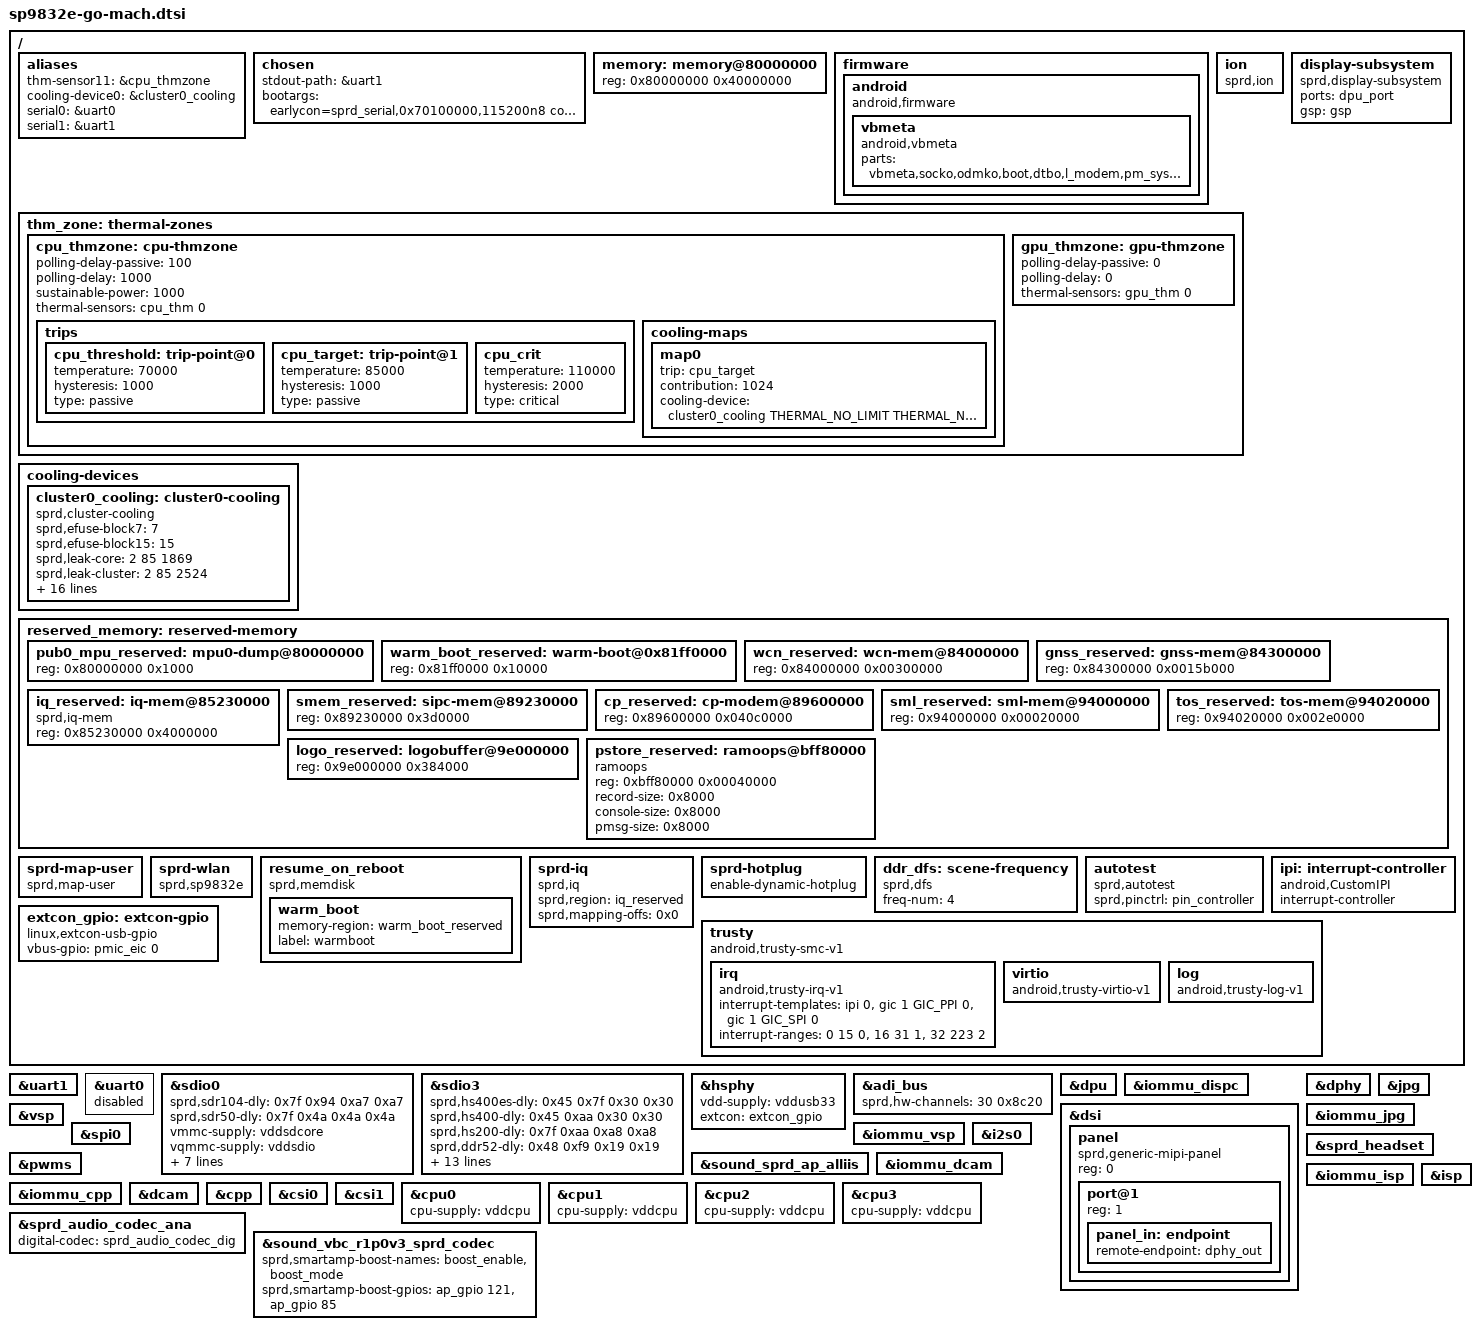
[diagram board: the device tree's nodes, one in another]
/*
 * Spreadtrum SP98x0 board common DTS file
 *
 * Copyright (C) 2019, Spreadtrum Communications Inc.
 *
 * This file is licensed under a dual GPLv2 or X11 license.
 */

#include <dt-bindings/thermal/thermal.h>
#include "sc9832e-modem.dtsi"

/ {
	aliases {
		thm-sensor11 = &cpu_thmzone;
		cooling-device0 = &cluster0_cooling;
		serial0 = &uart0;
		serial1 = &uart1;
	};

	chosen: chosen {
		stdout-path = &uart1;
		bootargs = "earlycon=sprd_serial,0x70100000,115200n8 console=ttyS1,115200n8 loglevel=1 init=/init root=/dev/ram0 rw vmalloc=360M printk.devkmsg=on androidboot.boot_devices=soc/soc:ap-ahb/20600000.sdio";
	};

	memory: memory@80000000 {
		device_type = "memory";
		reg = <0x80000000 0x40000000>;
	};

	firmware {
		android {
			compatible = "android,firmware";
			vbmeta {
				compatible = "android,vbmeta";
				parts = "vbmeta,socko,odmko,boot,dtbo,l_modem,pm_sys,l_ldsp,l_gdsp";
			};
		};
	};

	ion: ion {
		compatible = "sprd,ion";
		#address-cells = <1>;
		#size-cells = <0>;

	};

	thm_zone: thermal-zones {

		cpu_thmzone: cpu-thmzone {
			polling-delay-passive = <100>;
			polling-delay = <1000>;
			sustainable-power = <1000>;
			thermal-sensors = <&cpu_thm 0>;
			trips {
				cpu_threshold: trip-point@0 {
					temperature = <70000>;
					hysteresis = <1000>;
					type = "passive";
				};
				cpu_target: trip-point@1 {
					temperature = <85000>;
					hysteresis = <1000>;
					type = "passive";
				};
				cpu_crit: cpu_crit {
					temperature = <110000>;
					hysteresis = <2000>;
					type = "critical";
				};
			};

			cooling-maps {
				map0 {
					trip = <&cpu_target>;
					contribution = <1024>;
					cooling-device =
					<&cluster0_cooling
						THERMAL_NO_LIMIT
						THERMAL_NO_LIMIT>;
				};
			};

		};

		gpu_thmzone: gpu-thmzone {
			polling-delay-passive = <0>;
			polling-delay = <0>;
			thermal-sensors = <&gpu_thm 0>;
		};
	};

	cooling-devices {
		cluster0_cooling: cluster0-cooling {
			compatible = "sprd,cluster-cooling";
			#cooling-cells = <2>; /* min followed by max */
			sprd,efuse-block7 = <7>;
			sprd,efuse-block15 = <15>;
			/* core_leak =                             */
			/*(LIT_LEAK[4:0]+1) x 2mA x 0.85V x 18.69% */
			sprd,leak-core = <2 85 1869>;
			/* cluster_leak =                           */
			/* (LIT_LEAK[4:0]+1) x 2mA x 0.85V x 25.24% */
			sprd,leak-cluster = <2 85 2524>;
			/*core Tscale = aT^3 + bT^2 + cT +di   */
			sprd,core-temp-scale =
			/* a*10^7   b*10^7      c*10^7     d*10^7 */
			<  34       (-3000)     147000     (-1367000)>;
			/*core Vscale = eV^3 + fV^2 + gV + h */
			sprd,core-voltage-scale =
			/* e*10^2   f*10^2     g*10^2  h*10^2*/
			<  2863     (-7860)    7541    (-2408)>;
			/*cluster Tscale = aT^3 + bT^2 + cT +di   */
			sprd,cluster-temp-scale =
			/* a*10^7   b*10^7      c*10^7     d*10^7 */
			<  26       (-2000)     115000     (-1000000)>;
			/*cluster Vscale = eV^3 + fV^2 + gV + h */
			sprd,cluster-voltage-scale =
			/* e*10^2   f*10^2     g*10^2  h*10^2*/
			<  1582     (-4201)    4063    (-1307)>;
			sprd,efuse-switch = <0>;
			sprd,hotplug-period = <10>;
			sprd,min-cpufreq = <768000>;
			sprd,min-cpunum = <4>;
			sprd,core-base = <267>;
			sprd,cluster-base = <294>;
			sprd,dynamic-core =
			/*Pdynperghz    Freq     Vbase  */
			< 850          768       900>;
			sprd,dynamic-cluster =
			/*Pdynperghz    Freq     Vbase  */
			< 980           768      900>;
		};
	};

	display-subsystem {
		compatible = "sprd,display-subsystem";
		ports = <&dpu_port>;
		gsp = <&gsp>;
	};

	reserved_memory: reserved-memory {
		#address-cells = <1>;
		#size-cells = <1>;
		ranges;

		pub0_mpu_reserved: mpu0-dump@80000000 {
			reg = <0x80000000 0x1000>;
		};

		warm_boot_reserved: warm-boot@0x81ff0000 {
			reg = <0x81ff0000 0x10000>; /* 64K */
		};

		/* must be 32M aligned */
		wcn_reserved: wcn-mem@84000000 {
			reg = <0x84000000 0x00300000>;
		};

		gnss_reserved: gnss-mem@84300000 {
			reg = <0x84300000 0x0015b000>;
		};

		/* Only used for iq, will be removed in normal mode by uboot */
		iq_reserved: iq-mem@85230000 {
			compatible = "sprd,iq-mem";
			reg = <0x85230000 0x4000000>;
		};

		smem_reserved: sipc-mem@89230000 {
			reg = <0x89230000 0x3d0000>;
		};

		/* cp_reserved = cp region + debug region */
		/* debug region: not reserved in normal mode, it */
		/* will be proccessed in u-boot */
		cp_reserved: cp-modem@89600000 {
			reg = <0x89600000 0x040c0000>;
		};

		/* must be 64M aligned */
		sml_reserved: sml-mem@94000000 {
			reg = <0x94000000 0x00020000>;
		};

		tos_reserved: tos-mem@94020000 {
			reg = <0x94020000 0x002e0000>;
		};

		logo_reserved: logobuffer@9e000000 {
			reg = <0x9e000000 0x384000>;
		};

		pstore_reserved: ramoops@bff80000 {
			compatible = "ramoops";
			reg = <0xbff80000 0x00040000>;
			record-size = <0x8000>;
			console-size = <0x8000>;
			pmsg-size = <0x8000>;
		};
	};

	sprd-map-user {
		compatible = "sprd,map-user";
	};

	sprd-wlan {
		 compatible = "sprd,sp9832e";
	};

	resume_on_reboot {
		compatible = "sprd,memdisk";

		warm_boot {
			memory-region = <&warm_boot_reserved>;
			label = "warmboot";
		};
	};

	sprd-iq {
		compatible = "sprd,iq";
		sprd,region = <&iq_reserved>;
		sprd,mapping-offs = <0x0>;
	};

	sprd-hotplug {
		enable-dynamic-hotplug;
	};

	ddr_dfs: scene-frequency {
		compatible = "sprd,dfs";
		freq-num = <4>;
	};

	autotest:autotest{
		compatible = "sprd,autotest";
		sprd,pinctrl = <&pin_controller>;
	};

	ipi: interrupt-controller {
		compatible = "android,CustomIPI";
		#interrupt-cells = <1>;
		interrupt-controller;
	};

	trusty {
		compatible = "android,trusty-smc-v1";
		irq {
			compatible = "android,trusty-irq-v1";
			interrupt-templates = <&ipi 0>,
						<&gic 1 GIC_PPI 0>,
						<&gic 1 GIC_SPI 0>;
				interrupt-ranges = < 0  15 0>,
						<16  31 1>,
						<32 223 2>;
		};

		virtio {
			compatible = "android,trusty-virtio-v1";
		};

		log {
			compatible = "android,trusty-log-v1";
		};
	};

	extcon_gpio: extcon-gpio {
		compatible = "linux,extcon-usb-gpio";
		vbus-gpio = <&pmic_eic 0 GPIO_ACTIVE_HIGH>;
	};
};

&uart1 {
	status = "okay";
};

&uart0 {
	status = "disabled";
};

&sdio0 {
	sprd,sdr104-dly = <0x7f 0x94 0xa7 0xa7>;
	sprd,sdr50-dly = <0x7f 0x4a 0x4a 0x4a>;
	vmmc-supply = <&vddsdcore>;
	vqmmc-supply = <&vddsdio>;
	voltage-ranges = <3000 3000>;
	bus-width = <4>;
	sd-uhs-sdr50;
	sprd,name = "sdio_sd";
	sprd,sdio-adma;
	no-sdio;
	no-mmc;
	status = "okay";
};

&sdio3 {
	sprd,hs400es-dly = <0x45 0x7f 0x30 0x30>;
	sprd,hs400-dly = <0x45 0xaa 0x30 0x30>;
	sprd,hs200-dly = <0x7f 0xaa 0xa8 0xa8>;
	sprd,ddr52-dly = <0x48 0xf9 0x19 0x19>;
	vmmc-supply = <&vddemmccore>;
	voltage-ranges = <3000 3000>;
	bus-width = <8>;
	non-removable;
	cap-mmc-hw-reset;
	mmc-hs400-enhanced-strobe;
	mmc-hs400-1_8v;
	mmc-hs200-1_8v;
	mmc-ddr-1_8v;
	sprd,name = "sdio_emmc";
	sprd,sdio-adma;
	no-sdio;
	no-sd;
	status = "okay";
};

&hsphy {
	vdd-supply = <&vddusb33>;
	extcon = <&extcon_gpio>;
};

&adi_bus {
	sprd,hw-channels = <30 0x8c20>;
};

&dpu {
	status = "okay";
};

&iommu_dispc {
	status = "okay";
};

&dsi {
	status = "okay";
	#address-cells = <1>;
	#size-cells = <0>;

	panel: panel {
		compatible = "sprd,generic-mipi-panel";
		#address-cells = <1>;
		#size-cells = <0>;
		reg = <0>;

		port@1 {
			reg = <1>;
			panel_in: endpoint {
				remote-endpoint = <&dphy_out>;
			};
		};
	};
};

&dphy {
	status = "okay";
};

&jpg {
	status = "okay";
};

&iommu_jpg {
	status = "okay";
};

&vsp {
	status = "okay";
};

&iommu_vsp {
	status = "okay";
};

&spi0 {
	/*used for fingerprint sensor*/
	status = "okay";
};

&i2s0 {
	status = "okay";
};

&sprd_headset {
	status = "okay";
};

&sound_sprd_ap_alliis {
	status = "okay";
};

&pwms {
	status = "okay";
};

&iommu_dcam {
	status = "okay";
};

&iommu_isp {
	status = "okay";
};

&iommu_cpp {
	status = "okay";
};

&dcam {
	status = "okay";
};

&isp {
	status = "okay";
};

&cpp {
	status = "okay";
};

&csi0 {
	status = "okay";
};

&csi1 {
	status = "okay";
};

&cpu0 {
	cpu-supply = <&vddcpu>;
};

&cpu1 {
	cpu-supply = <&vddcpu>;
};

&cpu2 {
	cpu-supply = <&vddcpu>;
};

&cpu3 {
	cpu-supply = <&vddcpu>;
};

&sprd_audio_codec_ana {
	status = "okay";
	digital-codec = <&sprd_audio_codec_dig>;
};

&sound_vbc_r1p0v3_sprd_codec {
	status = "okay";
	sprd,smartamp-boost-names = "boost_enable", "boost_mode";
	sprd,smartamp-boost-gpios = <&ap_gpio 121 0>,
				<&ap_gpio 85 0>;
};

